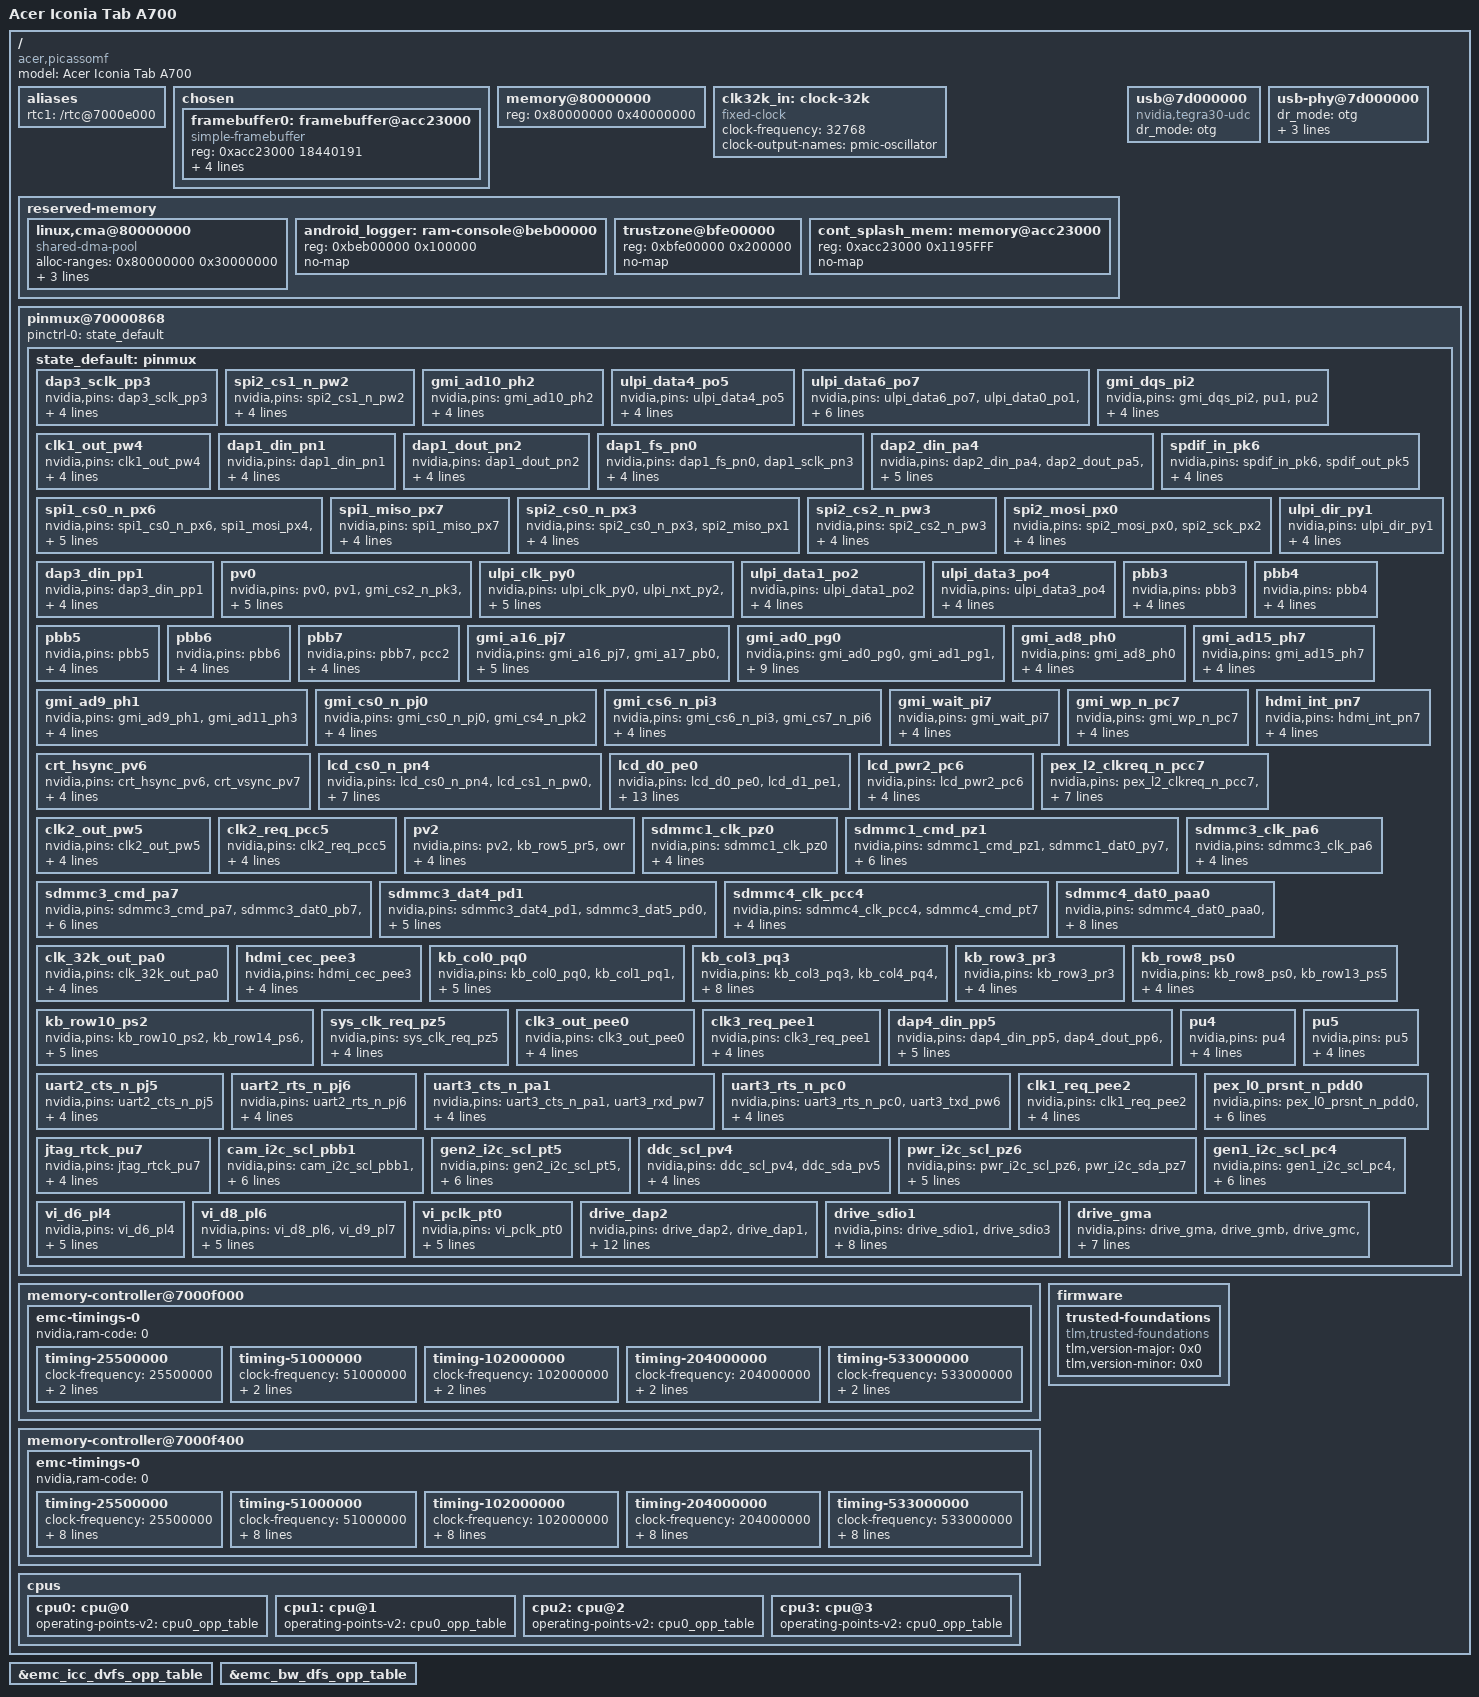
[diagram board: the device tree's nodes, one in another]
// SPDX-License-Identifier: GPL-2.0
/dts-v1/;
// /memreserve/ 0xbeb00000 0x100000;
#include <dt-bindings/input/gpio-keys.h>
#include <dt-bindings/input/input.h>
#include <dt-bindings/thermal/thermal.h>

#include "tegra30.dtsi"
#include "tegra30-cpu-opp.dtsi"
#include "tegra30-cpu-opp-microvolt.dtsi"

/ {
	model = "Acer Iconia Tab A700";
	compatible = "acer,picassomf", "nvidia,tegra30";

	aliases {
		rtc1 = "/rtc@7000e000";
	};

	chosen {
            #address-cells = <1>;
            #size-cells = <1>;
            ranges;

            framebuffer0: framebuffer@acc23000 {
                compatible = "simple-framebuffer";
                reg = <0xacc23000 18440191>;
                width = <1920>;
                height = <1200>;
                stride = <7680>;
                format = "a8r8g8b8";
                status = "okay";
            };
	};

	memory@80000000 {
		reg = <0x80000000 0x40000000>;
	};

	clk32k_in: clock-32k {
		compatible = "fixed-clock";
		#clock-cells = <0>;
		clock-frequency = <32768>;
		clock-output-names = "pmic-oscillator";
	};

	reserved-memory {
		#address-cells = <1>;
		#size-cells = <1>;
		ranges;

		linux,cma@80000000 {
			compatible = "shared-dma-pool";
			alloc-ranges = <0x80000000 0x30000000>;
			size = <0x10000000>; /* 256MiB */
			linux,cma-default;
			reusable;
		};

		android_logger: ram-console@beb00000 {
			reg = <0xbeb00000 0x100000>;
			no-map;
		};

		trustzone@bfe00000 {
			reg = <0xbfe00000 0x200000>;
			no-map;
		};

		cont_splash_mem: memory@acc23000 {
			reg = <0xacc23000 0x1195FFF>;
			no-map;
		};
	};

        usb@7d000000 {
                compatible = "nvidia,tegra30-udc";
                status = "okay";
                dr_mode = "otg";
        };

        usb-phy@7d000000 {
                status = "okay";
                dr_mode = "otg";
                nvidia,hssync-start-delay = <0>;
                nvidia,xcvr-lsfslew = <2>;
                nvidia,xcvr-lsrslew = <2>;
        };

    pinmux@70000868 {
        pinctrl-names = "default";
        pinctrl-0 = <&state_default>;

        state_default: pinmux {
            dap3_sclk_pp3 {
                nvidia,pins = "dap3_sclk_pp3";
                nvidia,function = "i2s2";
                nvidia,pull = <TEGRA_PIN_PULL_DOWN>;
                nvidia,tristate = <TEGRA_PIN_DISABLE>;
                nvidia,enable-input = <TEGRA_PIN_DISABLE>;
            };

            spi2_cs1_n_pw2 {
                nvidia,pins = "spi2_cs1_n_pw2";
                nvidia,function = "spi2";
                nvidia,pull = <TEGRA_PIN_PULL_UP>;
                nvidia,tristate = <TEGRA_PIN_ENABLE>;
                nvidia,enable-input = <TEGRA_PIN_ENABLE>;
            };

            gmi_ad10_ph2 {
                nvidia,pins = "gmi_ad10_ph2";
                nvidia,function = "nand";
                nvidia,pull = <TEGRA_PIN_PULL_DOWN>;
                nvidia,tristate = <TEGRA_PIN_DISABLE>;
                nvidia,enable-input = <TEGRA_PIN_DISABLE>;
            };

            ulpi_data4_po5 {
                nvidia,pins = "ulpi_data4_po5";
                nvidia,function = "uarta";
                nvidia,pull = <TEGRA_PIN_PULL_UP>;
                nvidia,tristate = <TEGRA_PIN_DISABLE>;
                nvidia,enable-input = <TEGRA_PIN_ENABLE>;
            };

            ulpi_data6_po7 {
                nvidia,pins = "ulpi_data6_po7", "ulpi_data0_po1", "ulpi_data2_po3", "ulpi_data5_po6", "ulpi_data7_po0";
                nvidia,function = "uarta";
                nvidia,pull = <TEGRA_PIN_PULL_NONE>;
                nvidia,tristate = <TEGRA_PIN_DISABLE>;
                nvidia,enable-input = <TEGRA_PIN_DISABLE>;
            };

            gmi_dqs_pi2 {
                nvidia,pins = "gmi_dqs_pi2", "pu1", "pu2";
                nvidia,function = "rsvd1";
                nvidia,pull = <TEGRA_PIN_PULL_NONE>;
                nvidia,tristate = <TEGRA_PIN_DISABLE>;
                nvidia,enable-input = <TEGRA_PIN_DISABLE>;
            };

            clk1_out_pw4 {
                nvidia,pins = "clk1_out_pw4";
                nvidia,function = "extperiph1";
                nvidia,pull = <TEGRA_PIN_PULL_NONE>;
                nvidia,tristate = <TEGRA_PIN_DISABLE>;
                nvidia,enable-input = <TEGRA_PIN_ENABLE>;
            };

            dap1_din_pn1 {
                nvidia,pins = "dap1_din_pn1";
                nvidia,function = "i2s0";
                nvidia,pull = <TEGRA_PIN_PULL_DOWN>;
                nvidia,tristate = <TEGRA_PIN_DISABLE>;
                nvidia,enable-input = <TEGRA_PIN_DISABLE>;
            };

            dap1_dout_pn2 {
                nvidia,pins = "dap1_dout_pn2";
                nvidia,function = "i2s0";
                nvidia,pull = <TEGRA_PIN_PULL_DOWN>;
                nvidia,tristate = <TEGRA_PIN_ENABLE>;
                nvidia,enable-input = <TEGRA_PIN_ENABLE>;
            };

            dap1_fs_pn0 {
                nvidia,pins = "dap1_fs_pn0", "dap1_sclk_pn3";
                nvidia,function = "i2s0";
                nvidia,pull = <TEGRA_PIN_PULL_NONE>;
                nvidia,tristate = <TEGRA_PIN_DISABLE>;
                nvidia,enable-input = <TEGRA_PIN_DISABLE>;
            };

            dap2_din_pa4 {
                nvidia,pins = "dap2_din_pa4", "dap2_dout_pa5", "dap2_fs_pa2", "dap2_sclk_pa3";
                nvidia,function = "i2s1";
                nvidia,pull = <TEGRA_PIN_PULL_NONE>;
                nvidia,tristate = <TEGRA_PIN_DISABLE>;
                nvidia,enable-input = <TEGRA_PIN_ENABLE>;
            };

            spdif_in_pk6 {
                nvidia,pins = "spdif_in_pk6", "spdif_out_pk5";
                nvidia,function = "spdif";
                nvidia,pull = <TEGRA_PIN_PULL_NONE>;
                nvidia,tristate = <TEGRA_PIN_DISABLE>;
                nvidia,enable-input = <TEGRA_PIN_DISABLE>;
            };

            spi1_cs0_n_px6 {
                nvidia,pins = "spi1_cs0_n_px6", "spi1_mosi_px4", "spi1_sck_px5";
                nvidia,function = "spi1";
                nvidia,pull = <TEGRA_PIN_PULL_NONE>;
                nvidia,tristate = <TEGRA_PIN_DISABLE>;
                nvidia,enable-input = <TEGRA_PIN_DISABLE>;
            };

            spi1_miso_px7 {
                nvidia,pins = "spi1_miso_px7";
                nvidia,function = "spi1";
                nvidia,pull = <TEGRA_PIN_PULL_DOWN>;
                nvidia,tristate = <TEGRA_PIN_ENABLE>;
                nvidia,enable-input = <TEGRA_PIN_ENABLE>;
            };

            spi2_cs0_n_px3 {
                nvidia,pins = "spi2_cs0_n_px3", "spi2_miso_px1";
                nvidia,function = "spi2";
                nvidia,pull = <TEGRA_PIN_PULL_NONE>;
                nvidia,tristate = <TEGRA_PIN_ENABLE>;
                nvidia,enable-input = <TEGRA_PIN_ENABLE>;
            };

            spi2_cs2_n_pw3 {
                nvidia,pins = "spi2_cs2_n_pw3";
                nvidia,function = "spi2";
                nvidia,pull = <TEGRA_PIN_PULL_DOWN>;
                nvidia,tristate = <TEGRA_PIN_ENABLE>;
                nvidia,enable-input = <TEGRA_PIN_ENABLE>;
            };

            spi2_mosi_px0 {
                nvidia,pins = "spi2_mosi_px0", "spi2_sck_px2";
                nvidia,function = "spi2";
                nvidia,pull = <TEGRA_PIN_PULL_NONE>;
                nvidia,tristate = <TEGRA_PIN_DISABLE>;
                nvidia,enable-input = <TEGRA_PIN_DISABLE>;
            };

            dap3_din_pp1 {
                nvidia,pins = "dap3_din_pp1";
                nvidia,function = "i2s2";
                nvidia,pull = <TEGRA_PIN_PULL_NONE>;
                nvidia,tristate = <TEGRA_PIN_DISABLE>;
                nvidia,enable-input = <TEGRA_PIN_DISABLE>;
            };

            pv0 {
                nvidia,pins = "pv0", "pv1", "gmi_cs2_n_pk3", "gmi_iordy_pi5";
                nvidia,function = "rsvd1";
                nvidia,pull = <TEGRA_PIN_PULL_NONE>;
                nvidia,tristate = <TEGRA_PIN_ENABLE>;
                nvidia,enable-input = <TEGRA_PIN_ENABLE>;
            };

            ulpi_clk_py0 {
                nvidia,pins = "ulpi_clk_py0", "ulpi_nxt_py2", "ulpi_stp_py3";
                nvidia,function = "uartd";
                nvidia,pull = <TEGRA_PIN_PULL_NONE>;
                nvidia,tristate = <TEGRA_PIN_DISABLE>;
                nvidia,enable-input = <TEGRA_PIN_DISABLE>;
            };

            ulpi_data1_po2 {
                nvidia,pins = "ulpi_data1_po2";
                nvidia,function = "uarta";
                nvidia,pull = <TEGRA_PIN_PULL_NONE>;
                nvidia,tristate = <TEGRA_PIN_DISABLE>;
                nvidia,enable-input = <TEGRA_PIN_ENABLE>;
            };

            ulpi_data3_po4 {
                nvidia,pins = "ulpi_data3_po4";
                nvidia,function = "uarta";
                nvidia,pull = <TEGRA_PIN_PULL_NONE>;
                nvidia,tristate = <TEGRA_PIN_ENABLE>;
                nvidia,enable-input = <TEGRA_PIN_ENABLE>;
            };

            ulpi_dir_py1 {
                nvidia,pins = "ulpi_dir_py1";
                nvidia,function = "uartd";
                nvidia,pull = <TEGRA_PIN_PULL_NONE>;
                nvidia,tristate = <TEGRA_PIN_DISABLE>;
                nvidia,enable-input = <TEGRA_PIN_ENABLE>;
            };

            pbb3 {
                nvidia,pins = "pbb3";
                nvidia,function = "vgp3";
                nvidia,pull = <TEGRA_PIN_PULL_NONE>;
                nvidia,tristate = <TEGRA_PIN_DISABLE>;
                nvidia,enable-input = <TEGRA_PIN_DISABLE>;
            };

            pbb4 {
                nvidia,pins = "pbb4";
                nvidia,function = "vgp4";
                nvidia,pull = <TEGRA_PIN_PULL_NONE>;
                nvidia,tristate = <TEGRA_PIN_DISABLE>;
                nvidia,enable-input = <TEGRA_PIN_DISABLE>;
            };

            pbb5 {
                nvidia,pins = "pbb5";
                nvidia,function = "vgp5";
                nvidia,pull = <TEGRA_PIN_PULL_NONE>;
                nvidia,tristate = <TEGRA_PIN_DISABLE>;
                nvidia,enable-input = <TEGRA_PIN_DISABLE>;
            };

            pbb6 {
                nvidia,pins = "pbb6";
                nvidia,function = "vgp6";
                nvidia,pull = <TEGRA_PIN_PULL_NONE>;
                nvidia,tristate = <TEGRA_PIN_ENABLE>;
                nvidia,enable-input = <TEGRA_PIN_ENABLE>;
            };

            pbb7 {
                nvidia,pins = "pbb7", "pcc2";
                nvidia,function = "i2s4";
                nvidia,pull = <TEGRA_PIN_PULL_NONE>;
                nvidia,tristate = <TEGRA_PIN_DISABLE>;
                nvidia,enable-input = <TEGRA_PIN_DISABLE>;
            };

            gmi_a16_pj7 {
                nvidia,pins = "gmi_a16_pj7", "gmi_a17_pb0", "gmi_a18_pb1";
                nvidia,function = "spi4";
                nvidia,pull = <TEGRA_PIN_PULL_NONE>;
                nvidia,tristate = <TEGRA_PIN_DISABLE>;
                nvidia,enable-input = <TEGRA_PIN_DISABLE>;
            };



            gmi_ad0_pg0 {
                nvidia,pins = "gmi_ad0_pg0", "gmi_ad1_pg1", "gmi_ad2_pg2", "gmi_ad3_pg3", "gmi_ad4_pg4", "gmi_ad5_pg5", "gmi_ad6_pg6", "gmi_ad7_pg7", "gmi_ad12_ph4", "gmi_ad13_ph5", "gmi_ad14_ph6", "gmi_adv_n_pk0", "gmi_clk_pk1", "gmi_cs1_n_pj2", "gmi_cs3_n_pk4", "gmi_oe_n_pi1", "gmi_wr_n_pi0";
                nvidia,function = "nand";
                nvidia,pull = <TEGRA_PIN_PULL_NONE>;
                nvidia,tristate = <TEGRA_PIN_ENABLE>;
                nvidia,enable-input = <TEGRA_PIN_ENABLE>;
            };

            gmi_ad8_ph0 {
                nvidia,pins = "gmi_ad8_ph0";
                nvidia,function = "pwm0";
                nvidia,pull = <TEGRA_PIN_PULL_NONE>;
                nvidia,tristate = <TEGRA_PIN_DISABLE>;
                nvidia,enable-input = <TEGRA_PIN_DISABLE>;
            };

            gmi_ad9_ph1 {
                nvidia,pins = "gmi_ad9_ph1", "gmi_ad11_ph3";
                nvidia,function = "nand";
                nvidia,pull = <TEGRA_PIN_PULL_NONE>;
                nvidia,tristate = <TEGRA_PIN_DISABLE>;
                nvidia,enable-input = <TEGRA_PIN_DISABLE>;
            };

            gmi_ad15_ph7 {
                nvidia,pins = "gmi_ad15_ph7";
                nvidia,function = "nand";
                nvidia,pull = <TEGRA_PIN_PULL_NONE>;
                nvidia,tristate = <TEGRA_PIN_DISABLE>;
                nvidia,enable-input = <TEGRA_PIN_ENABLE>;
            };

            gmi_cs0_n_pj0 {
                nvidia,pins = "gmi_cs0_n_pj0", "gmi_cs4_n_pk2";
                nvidia,function = "nand";
                nvidia,pull = <TEGRA_PIN_PULL_UP>;
                nvidia,tristate = <TEGRA_PIN_ENABLE>;
                nvidia,enable-input = <TEGRA_PIN_ENABLE>;
            };

            gmi_cs6_n_pi3 {
                nvidia,pins = "gmi_cs6_n_pi3", "gmi_cs7_n_pi6";
                nvidia,function = "nand_alt";
                nvidia,pull = <TEGRA_PIN_PULL_NONE>;
                nvidia,tristate = <TEGRA_PIN_ENABLE>;
                nvidia,enable-input = <TEGRA_PIN_ENABLE>;
            };

            gmi_wait_pi7 {
                nvidia,pins = "gmi_wait_pi7";
                nvidia,function = "nand";
                nvidia,pull = <TEGRA_PIN_PULL_UP>;
                nvidia,tristate = <TEGRA_PIN_DISABLE>;
                nvidia,enable-input = <TEGRA_PIN_DISABLE>;
            };

            gmi_wp_n_pc7 {
                nvidia,pins = "gmi_wp_n_pc7";
                nvidia,function = "rsvd1";
                nvidia,pull = <TEGRA_PIN_PULL_UP>;
                nvidia,tristate = <TEGRA_PIN_DISABLE>;
                nvidia,enable-input = <TEGRA_PIN_ENABLE>;
            };

            crt_hsync_pv6 {
                nvidia,pins = "crt_hsync_pv6", "crt_vsync_pv7";
                nvidia,function = "crt";
                nvidia,pull = <TEGRA_PIN_PULL_NONE>;
                nvidia,tristate = <TEGRA_PIN_DISABLE>;
                nvidia,enable-input = <TEGRA_PIN_DISABLE>;
            };

            hdmi_int_pn7 {
                nvidia,pins = "hdmi_int_pn7";
                nvidia,function = "hdmi";
                nvidia,pull = <TEGRA_PIN_PULL_NONE>;
                nvidia,tristate = <TEGRA_PIN_ENABLE>;
                nvidia,enable-input = <TEGRA_PIN_ENABLE>;
            };

            lcd_cs0_n_pn4 {
                nvidia,pins = "lcd_cs0_n_pn4", "lcd_cs1_n_pw0", "lcd_dc0_pn6", "lcd_dc1_pd2", "lcd_m1_pw1", "lcd_pwr0_pb2", "lcd_pwr1_pc1", "lcd_sck_pz4", "lcd_sdin_pz2", "lcd_sdout_pn5", "lcd_wr_n_pz3";
                nvidia,function = "displaya";
                nvidia,pull = <TEGRA_PIN_PULL_NONE>;
                nvidia,tristate = <TEGRA_PIN_DISABLE>;
                nvidia,enable-input = <TEGRA_PIN_DISABLE>;
            };

            lcd_d0_pe0 {
                nvidia,pins = "lcd_d0_pe0", "lcd_d1_pe1", "lcd_d2_pe2", "lcd_d3_pe3", "lcd_d4_pe4", "lcd_d5_pe5", "lcd_d6_pe6", "lcd_d7_pe7", "lcd_d8_pf0", "lcd_d9_pf1", "lcd_d10_pf2", "lcd_d11_pf3", "lcd_d12_pf4", "lcd_d13_pf5", "lcd_d14_pf6", "lcd_d15_pf7", "lcd_d16_pm0", "lcd_d17_pm1", "lcd_d18_pm2", "lcd_d19_pm3", "lcd_d20_pm4", "lcd_d21_pm5", "lcd_d22_pm6", "lcd_d23_pm7", "lcd_de_pj1", "lcd_hsync_pj3", "lcd_pclk_pb3", "lcd_vsync_pj4";
                nvidia,function = "displaya";
                nvidia,pull = <TEGRA_PIN_PULL_NONE>;
                nvidia,tristate = <TEGRA_PIN_DISABLE>;
                nvidia,enable-input = <TEGRA_PIN_ENABLE>;
            };

            lcd_pwr2_pc6 {
                nvidia,pins = "lcd_pwr2_pc6";
                nvidia,function = "displaya";
                nvidia,pull = <TEGRA_PIN_PULL_DOWN>;
                nvidia,tristate = <TEGRA_PIN_DISABLE>;
                nvidia,enable-input = <TEGRA_PIN_DISABLE>;
            };

            pex_l2_clkreq_n_pcc7 {
                nvidia,pins = "pex_l2_clkreq_n_pcc7", "pex_l2_prsnt_n_pdd7", "pex_l2_rst_n_pcc6", "pex_wake_n_pdd3", "pex_l0_rst_n_pdd1", "pex_l1_rst_n_pdd5";
                nvidia,function = "pcie";
                nvidia,pull = <TEGRA_PIN_PULL_NONE>;
                nvidia,tristate = <TEGRA_PIN_DISABLE>;
                nvidia,enable-input = <TEGRA_PIN_DISABLE>;
            };

            clk2_out_pw5 {
                nvidia,pins = "clk2_out_pw5";
                nvidia,function = "extperiph2";
                nvidia,pull = <TEGRA_PIN_PULL_UP>;
                nvidia,tristate = <TEGRA_PIN_DISABLE>;
                nvidia,enable-input = <TEGRA_PIN_DISABLE>;
            };

            clk2_req_pcc5 {
                nvidia,pins = "clk2_req_pcc5";
                nvidia,function = "dap";
                nvidia,pull = <TEGRA_PIN_PULL_NONE>;
                nvidia,tristate = <TEGRA_PIN_DISABLE>;
                nvidia,enable-input = <TEGRA_PIN_DISABLE>;
            };

            pv2 {
                nvidia,pins = "pv2", "kb_row5_pr5", "owr";
                nvidia,function = "owr";
                nvidia,pull = <TEGRA_PIN_PULL_NONE>;
                nvidia,tristate = <TEGRA_PIN_DISABLE>;
                nvidia,enable-input = <TEGRA_PIN_DISABLE>;
            };

            sdmmc1_clk_pz0 {
                nvidia,pins = "sdmmc1_clk_pz0";
                nvidia,function = "sdmmc1";
                nvidia,pull = <TEGRA_PIN_PULL_NONE>;
                nvidia,tristate = <TEGRA_PIN_DISABLE>;
                nvidia,enable-input = <TEGRA_PIN_ENABLE>;
            };

            sdmmc1_cmd_pz1 {
                nvidia,pins = "sdmmc1_cmd_pz1", "sdmmc1_dat0_py7", "sdmmc1_dat1_py6", "sdmmc1_dat2_py5", "sdmmc1_dat3_py4";
                nvidia,function = "sdmmc1";
                nvidia,pull = <TEGRA_PIN_PULL_UP>;
                nvidia,tristate = <TEGRA_PIN_DISABLE>;
                nvidia,enable-input = <TEGRA_PIN_ENABLE>;
            };

            sdmmc3_clk_pa6 {
                nvidia,pins = "sdmmc3_clk_pa6";
                nvidia,function = "sdmmc3";
                nvidia,pull = <TEGRA_PIN_PULL_NONE>;
                nvidia,tristate = <TEGRA_PIN_DISABLE>;
                nvidia,enable-input = <TEGRA_PIN_ENABLE>;
            };

            sdmmc3_cmd_pa7 {
                nvidia,pins = "sdmmc3_cmd_pa7", "sdmmc3_dat0_pb7", "sdmmc3_dat1_pb6", "sdmmc3_dat2_pb5", "sdmmc3_dat3_pb4";
                nvidia,function = "sdmmc3";
                nvidia,pull = <TEGRA_PIN_PULL_UP>;
                nvidia,tristate = <TEGRA_PIN_DISABLE>;
                nvidia,enable-input = <TEGRA_PIN_ENABLE>;
            };

            sdmmc3_dat4_pd1 {
                nvidia,pins = "sdmmc3_dat4_pd1", "sdmmc3_dat5_pd0", "sdmmc3_dat6_pd3", "sdmmc3_dat7_pd4";
                nvidia,function = "sdmmc3";
                nvidia,pull = <TEGRA_PIN_PULL_NONE>;
                nvidia,tristate = <TEGRA_PIN_DISABLE>;
                nvidia,enable-input = <TEGRA_PIN_DISABLE>;
            };

            sdmmc4_clk_pcc4 {
                nvidia,pins = "sdmmc4_clk_pcc4", "sdmmc4_cmd_pt7";
                nvidia,function = "sdmmc4";
                nvidia,pull = <TEGRA_PIN_PULL_NONE>;
                nvidia,tristate = <TEGRA_PIN_DISABLE>;
                nvidia,enable-input = <TEGRA_PIN_ENABLE>;
            };

            sdmmc4_dat0_paa0 {
                nvidia,pins = "sdmmc4_dat0_paa0", "sdmmc4_dat1_paa1", "sdmmc4_dat2_paa2", "sdmmc4_dat3_paa3", "sdmmc4_dat4_paa4", "sdmmc4_dat5_paa5", "sdmmc4_dat6_paa6", "sdmmc4_dat7_paa7";
                nvidia,function = "sdmmc4";
                nvidia,pull = <TEGRA_PIN_PULL_UP>;
                nvidia,tristate = <TEGRA_PIN_DISABLE>;
                nvidia,enable-input = <TEGRA_PIN_ENABLE>;
            };

            clk_32k_out_pa0 {
                nvidia,pins = "clk_32k_out_pa0";
                nvidia,function = "blink";
                nvidia,pull = <TEGRA_PIN_PULL_NONE>;
                nvidia,tristate = <TEGRA_PIN_DISABLE>;
                nvidia,enable-input = <TEGRA_PIN_DISABLE>;
            };

            hdmi_cec_pee3 {
                nvidia,pins = "hdmi_cec_pee3";
                nvidia,function = "cec";
                nvidia,pull = <TEGRA_PIN_PULL_NONE>;
                nvidia,tristate = <TEGRA_PIN_DISABLE>;
                nvidia,enable-input = <TEGRA_PIN_ENABLE>;
            };

            kb_col0_pq0 {
                nvidia,pins = "kb_col0_pq0", "kb_col1_pq1", "kb_col2_pq2", "kb_row12_ps4";
                nvidia,function = "kbc";
                nvidia,pull = <TEGRA_PIN_PULL_UP>;
                nvidia,tristate = <TEGRA_PIN_ENABLE>;
                nvidia,enable-input = <TEGRA_PIN_ENABLE>;
            };

            kb_col3_pq3 {
                nvidia,pins = "kb_col3_pq3", "kb_col4_pq4", "kb_col5_pq5", "kb_col6_pq6", "kb_col7_pq7", "kb_row0_pr0", "kb_row2_pr2", "kb_row4_pr4", "kb_row6_pr6", "kb_row7_pr7", "kb_row9_ps1", "kb_row11_ps3";
                nvidia,function = "kbc";
                nvidia,pull = <TEGRA_PIN_PULL_NONE>;
                nvidia,tristate = <TEGRA_PIN_DISABLE>;
                nvidia,enable-input = <TEGRA_PIN_DISABLE>;
            };

            kb_row3_pr3 {
                nvidia,pins = "kb_row3_pr3";
                nvidia,function = "kbc";
                nvidia,pull = <TEGRA_PIN_PULL_UP>;
                nvidia,tristate = <TEGRA_PIN_DISABLE>;
                nvidia,enable-input = <TEGRA_PIN_DISABLE>;
            };

            kb_row8_ps0 {
                nvidia,pins = "kb_row8_ps0", "kb_row13_ps5";
                nvidia,function = "kbc";
                nvidia,pull = <TEGRA_PIN_PULL_DOWN>;
                nvidia,tristate = <TEGRA_PIN_ENABLE>;
                nvidia,enable-input = <TEGRA_PIN_ENABLE>;
            };

            kb_row10_ps2 {
                nvidia,pins = "kb_row10_ps2", "kb_row14_ps6", "kb_row15_ps7";
                nvidia,function = "kbc";
                nvidia,pull = <TEGRA_PIN_PULL_NONE>;
                nvidia,tristate = <TEGRA_PIN_ENABLE>;
                nvidia,enable-input = <TEGRA_PIN_ENABLE>;
            };

            sys_clk_req_pz5 {
                nvidia,pins = "sys_clk_req_pz5";
                nvidia,function = "sysclk";
                nvidia,pull = <TEGRA_PIN_PULL_NONE>;
                nvidia,tristate = <TEGRA_PIN_DISABLE>;
                nvidia,enable-input = <TEGRA_PIN_DISABLE>;
            };

            clk3_out_pee0 {
                nvidia,pins = "clk3_out_pee0";
                nvidia,function = "extperiph3";
                nvidia,pull = <TEGRA_PIN_PULL_NONE>;
                nvidia,tristate = <TEGRA_PIN_DISABLE>;
                nvidia,enable-input = <TEGRA_PIN_DISABLE>;
            };

            clk3_req_pee1 {
                nvidia,pins = "clk3_req_pee1";
                nvidia,function = "dev3";
                nvidia,pull = <TEGRA_PIN_PULL_NONE>;
                nvidia,tristate = <TEGRA_PIN_DISABLE>;
                nvidia,enable-input = <TEGRA_PIN_DISABLE>;
            };

            dap4_din_pp5 {
                nvidia,pins = "dap4_din_pp5", "dap4_dout_pp6", "dap4_fs_pp4", "dap4_sclk_pp7";
                nvidia,function = "i2s3";
                nvidia,pull = <TEGRA_PIN_PULL_NONE>;
                nvidia,tristate = <TEGRA_PIN_DISABLE>;
                nvidia,enable-input = <TEGRA_PIN_ENABLE>;
            };

            pu4 {
                nvidia,pins = "pu4";
                nvidia,function = "pwm1";
                nvidia,pull = <TEGRA_PIN_PULL_NONE>;
                nvidia,tristate = <TEGRA_PIN_DISABLE>;
                nvidia,enable-input = <TEGRA_PIN_DISABLE>;
            };

            pu5 {
                nvidia,pins = "pu5";
                nvidia,function = "pwm2";
                nvidia,pull = <TEGRA_PIN_PULL_NONE>;
                nvidia,tristate = <TEGRA_PIN_ENABLE>;
                nvidia,enable-input = <TEGRA_PIN_ENABLE>;
            };

            uart2_cts_n_pj5 {
                nvidia,pins = "uart2_cts_n_pj5";
                nvidia,function = "uartb";
                nvidia,pull = <TEGRA_PIN_PULL_NONE>;
                nvidia,tristate = <TEGRA_PIN_DISABLE>;
                nvidia,enable-input = <TEGRA_PIN_ENABLE>;
            };

            uart2_rts_n_pj6 {
                nvidia,pins = "uart2_rts_n_pj6";
                nvidia,function = "uartb";
                nvidia,pull = <TEGRA_PIN_PULL_NONE>;
                nvidia,tristate = <TEGRA_PIN_DISABLE>;
                nvidia,enable-input = <TEGRA_PIN_DISABLE>;
            };

            uart3_cts_n_pa1 {
                nvidia,pins = "uart3_cts_n_pa1", "uart3_rxd_pw7";
                nvidia,function = "uartc";
                nvidia,pull = <TEGRA_PIN_PULL_NONE>;
                nvidia,tristate = <TEGRA_PIN_DISABLE>;
                nvidia,enable-input = <TEGRA_PIN_ENABLE>;
            };

            uart3_rts_n_pc0 {
                nvidia,pins = "uart3_rts_n_pc0", "uart3_txd_pw6";
                nvidia,function = "uartc";
                nvidia,pull = <TEGRA_PIN_PULL_NONE>;
                nvidia,tristate = <TEGRA_PIN_DISABLE>;
                nvidia,enable-input = <TEGRA_PIN_DISABLE>;
            };

            clk1_req_pee2 {
                nvidia,pins = "clk1_req_pee2";
                nvidia,function = "dap";
                nvidia,pull = <TEGRA_PIN_PULL_NONE>;
                nvidia,tristate = <TEGRA_PIN_DISABLE>;
                nvidia,enable-input = <TEGRA_PIN_ENABLE>;
            };

            pex_l0_prsnt_n_pdd0 {
                nvidia,pins = "pex_l0_prsnt_n_pdd0", "pex_l0_clkreq_n_pdd2", "pex_l1_prsnt_n_pdd4", "pex_l1_clkreq_n_pdd6";
                nvidia,function = "pcie";
                nvidia,pull = <TEGRA_PIN_PULL_NONE>;
                nvidia,tristate = <TEGRA_PIN_DISABLE>;
                nvidia,enable-input = <TEGRA_PIN_ENABLE>;
            };

            jtag_rtck_pu7 {
                nvidia,pins = "jtag_rtck_pu7";
                nvidia,function = "rtck";
                nvidia,pull = <TEGRA_PIN_PULL_NONE>;
                nvidia,tristate = <TEGRA_PIN_DISABLE>;
                nvidia,enable-input = <TEGRA_PIN_DISABLE>;
            };


            cam_i2c_scl_pbb1 {
                nvidia,pins = "cam_i2c_scl_pbb1", "cam_i2c_sda_pbb2";
                nvidia,function = "i2c3";
                nvidia,pull = <TEGRA_PIN_PULL_NONE>;
                nvidia,tristate = <TEGRA_PIN_DISABLE>;
                nvidia,enable-input = <TEGRA_PIN_ENABLE>;
                nvidia,open-drain = <TEGRA_PIN_ENABLE>;

            };


            gen2_i2c_scl_pt5 {
                nvidia,pins = "gen2_i2c_scl_pt5", "gen2_i2c_sda_pt6";
                nvidia,function = "i2c2";
                nvidia,pull = <TEGRA_PIN_PULL_NONE>;
                nvidia,tristate = <TEGRA_PIN_DISABLE>;
                nvidia,enable-input = <TEGRA_PIN_ENABLE>;
                nvidia,open-drain = <TEGRA_PIN_ENABLE>;

            };


            ddc_scl_pv4 {
                nvidia,pins = "ddc_scl_pv4", "ddc_sda_pv5";
                nvidia,function = "i2c4";
                nvidia,pull = <TEGRA_PIN_PULL_NONE>;
                nvidia,tristate = <TEGRA_PIN_DISABLE>;
                nvidia,enable-input = <TEGRA_PIN_ENABLE>;
                // nvidia,open-drain = <TEGRA_PIN_ENABLE>;

            };


            pwr_i2c_scl_pz6 {
                nvidia,pins = "pwr_i2c_scl_pz6", "pwr_i2c_sda_pz7";
                nvidia,function = "i2cpwr";
                nvidia,pull = <TEGRA_PIN_PULL_NONE>;
                nvidia,tristate = <TEGRA_PIN_DISABLE>;
                nvidia,enable-input = <TEGRA_PIN_ENABLE>;
                nvidia,open-drain = <TEGRA_PIN_ENABLE>;

            };


            gen1_i2c_scl_pc4 {
                nvidia,pins = "gen1_i2c_scl_pc4", "gen1_i2c_sda_pc5";
                nvidia,function = "i2c1";
                nvidia,pull = <TEGRA_PIN_PULL_NONE>;
                nvidia,tristate = <TEGRA_PIN_DISABLE>;
                nvidia,enable-input = <TEGRA_PIN_ENABLE>;
                nvidia,open-drain = <TEGRA_PIN_ENABLE>;

            };


            vi_d6_pl4 {
                nvidia,pins = "vi_d6_pl4";
                nvidia,function = "vi";
                nvidia,pull = <TEGRA_PIN_PULL_NONE>;
                nvidia,tristate = <TEGRA_PIN_DISABLE>;
                nvidia,enable-input = <TEGRA_PIN_DISABLE>;
                nvidia,ioreset = <0>;
            };

            vi_d8_pl6 {
                nvidia,pins = "vi_d8_pl6", "vi_d9_pl7";
                nvidia,function = "sdmmc2";
                nvidia,pull = <TEGRA_PIN_PULL_NONE>;
                nvidia,tristate = <TEGRA_PIN_DISABLE>;
                nvidia,enable-input = <TEGRA_PIN_ENABLE>;
                nvidia,ioreset = <0>;
            };

            vi_pclk_pt0 {
                nvidia,pins = "vi_pclk_pt0";
                nvidia,function = "rsvd1";
                nvidia,pull = <TEGRA_PIN_PULL_UP>;
                nvidia,tristate = <TEGRA_PIN_ENABLE>;
                nvidia,enable-input = <TEGRA_PIN_ENABLE>;
                nvidia,ioreset = <0>;
            };

            drive_dap2 {
                nvidia,pins = "drive_dap2", "drive_dap1", "drive_dbg", "drive_at5", "drive_gme", "drive_ddc", "drive_ao1", "drive_uart3";
                nvidia,high-speed-mode = <0>;
                nvidia,schmitt = <TEGRA_PIN_ENABLE>;
                nvidia,low-power-mode = <TEGRA_PIN_LP_DRIVE_DIV_1>;
                nvidia,pull-down-strength = <31>;
                nvidia,pull-up-strength = <31>;
                nvidia,slew-rate-rising = <TEGRA_PIN_SLEW_RATE_FASTEST>;
                nvidia,slew-rate-falling = <TEGRA_PIN_SLEW_RATE_FASTEST>;
            };

            drive_sdio1 {
                nvidia,pins = "drive_sdio1", "drive_sdio3";
                nvidia,high-speed-mode = <0>;
                nvidia,schmitt = <TEGRA_PIN_DISABLE>;
                // nvidia,low-power-mode = <TEGRA_PIN_LP_DRIVE_DIV_1>;
                nvidia,pull-down-strength = <46>;
                nvidia,pull-up-strength = <42>;
                nvidia,slew-rate-rising = <TEGRA_PIN_SLEW_RATE_FAST>;
                nvidia,slew-rate-falling = <TEGRA_PIN_SLEW_RATE_FAST>;
            };

            drive_gma {
                nvidia,pins = "drive_gma", "drive_gmb", "drive_gmc", "drive_gmd";
                nvidia,pull-down-strength = <9>;
                nvidia,pull-up-strength = <9>;
                nvidia,slew-rate-rising = <TEGRA_PIN_SLEW_RATE_SLOWEST>;
                nvidia,slew-rate-falling = <TEGRA_PIN_SLEW_RATE_SLOWEST>;
            };

        };
    };

memory-controller@7000f000 {
		emc-timings-0 {
			/* elpida */
			nvidia,ram-code = <0>;

			timing-25500000 {
				clock-frequency = <25500000>;

				nvidia,emem-configuration = < 0x00030003 0xc0000020
					0x00000001 0x00000001 0x00000002 0x00000000
					0x00000003 0x00000001 0x00000002 0x00000004
					0x00000001 0x00000000 0x00000002 0x00000002
					0x02020001 0x00060402 0x73e30303 0x001f0000 >;
			};

			timing-51000000 {
				clock-frequency = <51000000>;

				nvidia,emem-configuration = < 0x00010003 0xc0000020
					0x00000001 0x00000001 0x00000002 0x00000000
					0x00000003 0x00000001 0x00000002 0x00000004
					0x00000001 0x00000000 0x00000002 0x00000002
					0x02020001 0x00060402 0x72c30303 0x001f0000 >;
			};

			timing-102000000 {
				clock-frequency = <102000000>;

				nvidia,emem-configuration = < 0x00000003 0xc0000030
					0x00000001 0x00000001 0x00000003 0x00000001
					0x00000003 0x00000001 0x00000002 0x00000004
					0x00000001 0x00000000 0x00000002 0x00000002
					0x02020001 0x00060403 0x72430504 0x001f0000 >;
			};

			timing-204000000 {
				clock-frequency = <204000000>;

				nvidia,emem-configuration = < 0x00000006 0xc0000025
					0x00000001 0x00000001 0x00000006 0x00000003
					0x00000005 0x00000001 0x00000002 0x00000004
					0x00000001 0x00000000 0x00000003 0x00000002
					0x02030001 0x00070506 0x71e40a07 0x001f0000 >;
			};

			timing-533000000 {
				clock-frequency = <533000000>;

				nvidia,emem-configuration = < 0x0000000f 0xc0000060
					0x00000003 0x00000004 0x00000010 0x0000000a
					0x0000000d 0x00000002 0x00000002 0x00000008
					0x00000002 0x00000000 0x00000004 0x00000005
					0x05040002 0x00110b10 0x71c81811 0x001f0000 >;
			};
		};
	};

	memory-controller@7000f400 {
		emc-timings-0 {
			/* elpida */
			nvidia,ram-code = <0>;

			timing-25500000 {
				clock-frequency = <25500000>;

				nvidia,emc-auto-cal-interval = <0x001fffff>;
				nvidia,emc-mode-1 = <0x00010022>;
				nvidia,emc-mode-2 = <0x00020001>;
				nvidia,emc-mode-reset = <0x00000000>;
				nvidia,emc-zcal-cnt-long = <0x00000009>;
				nvidia,emc-cfg-periodic-qrst;

				nvidia,emc-configuration =  < 0x00000001
					0x00000003 0x00000002 0x00000002 0x00000004
					0x00000004 0x00000001 0x00000005 0x00000002
					0x00000002 0x00000001 0x00000001 0x00000000
					0x00000001 0x00000003 0x00000001 0x0000000b
					0x00000009 0x00000060 0x00000000 0x00000018
					0x00000001 0x00000001 0x00000002 0x00000000
					0x00000001 0x00000007 0x00000004 0x00000004
					0x00000003 0x00000008 0x00000004 0x00000004
					0x00000002 0x0000006b 0x00000004 0x00000004
					0x00000000 0x00000000 0x00004282 0x00780084
					0x00008000 0x000fc000 0x000fc000 0x000fc000
					0x000fc000 0x000fc000 0x000fc000 0x000fc000
					0x000fc000 0x00000000 0x00000000 0x00000000
					0x00000000 0x00000000 0x00000000 0x00000000
					0x00000000 0x00000000 0x00000000 0x00000000
					0x00000000 0x00000000 0x00000000 0x00000000
					0x00000000 0x000fc000 0x000fc000 0x000fc000
					0x000fc000 0x00100220 0x0800201c 0x00000000
					0x77ffc004 0x01f1f008 0x00000000 0x00000007
					0x08000068 0x08000000 0x00000802 0x00064000
					0x0000000a 0x00090009 0xa0f10000 0x00000000
					0x00000000 0x800001c5 0xe0000000 0xff00ff00 >;
			};

			timing-51000000 {
				clock-frequency = <51000000>;

				nvidia,emc-auto-cal-interval = <0x001fffff>;
				nvidia,emc-mode-1 = <0x00010022>;
				nvidia,emc-mode-2 = <0x00020001>;
				nvidia,emc-mode-reset = <0x00000000>;
				nvidia,emc-zcal-cnt-long = <0x00000009>;
				nvidia,emc-cfg-periodic-qrst;

				nvidia,emc-configuration =  < 0x00000003
					0x00000006 0x00000002 0x00000002 0x00000004
					0x00000004 0x00000001 0x00000005 0x00000002
					0x00000002 0x00000001 0x00000001 0x00000000
					0x00000001 0x00000003 0x00000001 0x0000000b
					0x00000009 0x000000c0 0x00000000 0x00000030
					0x00000001 0x00000001 0x00000002 0x00000000
					0x00000001 0x00000007 0x00000008 0x00000008
					0x00000003 0x00000008 0x00000004 0x00000004
					0x00000002 0x000000d5 0x00000004 0x00000004
					0x00000000 0x00000000 0x00004282 0x00780084
					0x00008000 0x000fc000 0x000fc000 0x000fc000
					0x000fc000 0x000fc000 0x000fc000 0x000fc000
					0x000fc000 0x00000000 0x00000000 0x00000000
					0x00000000 0x00000000 0x00000000 0x00000000
					0x00000000 0x00000000 0x00000000 0x00000000
					0x00000000 0x00000000 0x00000000 0x00000000
					0x00000000 0x000fc000 0x000fc000 0x000fc000
					0x000fc000 0x00100220 0x0800201c 0x00000000
					0x77ffc004 0x01f1f008 0x00000000 0x00000007
					0x08000068 0x08000000 0x00000802 0x00064000
					0x00000013 0x00090009 0xa0f10000 0x00000000
					0x00000000 0x80000287 0xe0000000 0xff00ff00 >;
			};

			timing-102000000 {
				clock-frequency = <102000000>;

				nvidia,emc-auto-cal-interval = <0x001fffff>;
				nvidia,emc-mode-1 = <0x00010022>;
				nvidia,emc-mode-2 = <0x00020001>;
				nvidia,emc-mode-reset = <0x00000000>;
				nvidia,emc-zcal-cnt-long = <0x0000000a>;
				nvidia,emc-cfg-periodic-qrst;

				nvidia,emc-configuration =  < 0x00000006
					0x0000000d 0x00000004 0x00000002 0x00000004
					0x00000004 0x00000001 0x00000005 0x00000002
					0x00000002 0x00000001 0x00000001 0x00000000
					0x00000001 0x00000003 0x00000001 0x0000000b
					0x00000009 0x00000181 0x00000000 0x00000060
					0x00000001 0x00000001 0x00000002 0x00000000
					0x00000001 0x00000007 0x0000000f 0x0000000f
					0x00000003 0x00000008 0x00000004 0x00000004
					0x00000002 0x000001a9 0x00000004 0x00000004
					0x00000000 0x00000000 0x00004282 0x00780084
					0x00008000 0x000fc000 0x000fc000 0x000fc000
					0x000fc000 0x000fc000 0x000fc000 0x000fc000
					0x000fc000 0x00000000 0x00000000 0x00000000
					0x00000000 0x00000000 0x00000000 0x00000000
					0x00000000 0x00000000 0x00000000 0x00000000
					0x00000000 0x00000000 0x00000000 0x00000000
					0x00000000 0x000fc000 0x000fc000 0x000fc000
					0x000fc000 0x00100220 0x0800201c 0x00000000
					0x77ffc004 0x01f1f008 0x00000000 0x00000007
					0x08000068 0x08000000 0x00000802 0x00064000
					0x00000025 0x00090009 0xa0f10000 0x00000000
					0x00000000 0x8000040b 0xe0000000 0xff00ff00 >;
			};

			timing-204000000 {
				clock-frequency = <204000000>;

				nvidia,emc-auto-cal-interval = <0x001fffff>;
				nvidia,emc-mode-1 = <0x00010042>;
				nvidia,emc-mode-2 = <0x00020001>;
				nvidia,emc-mode-reset = <0x00000000>;
				nvidia,emc-zcal-cnt-long = <0x00000013>;
				nvidia,emc-cfg-periodic-qrst;

				nvidia,emc-configuration =  < 0x0000000c
					0x0000001a 0x00000008 0x00000003 0x00000005
					0x00000004 0x00000001 0x00000006 0x00000003
					0x00000003 0x00000002 0x00000002 0x00000000
					0x00000001 0x00000003 0x00000001 0x0000000c
					0x0000000a 0x00000303 0x00000000 0x000000c0
					0x00000001 0x00000001 0x00000003 0x00000000
					0x00000001 0x00000007 0x0000001d 0x0000001d
					0x00000004 0x0000000b 0x00000005 0x00000004
					0x00000002 0x00000351 0x00000004 0x00000006
					0x00000000 0x00000000 0x00004282 0x00440084
					0x00008000 0x00080000 0x00080000 0x00080000
					0x00080000 0x00080000 0x00080000 0x00080000
					0x00080000 0x00000000 0x00000000 0x00000000
					0x00000000 0x00000000 0x00000000 0x00000000
					0x00000000 0x00000000 0x00000000 0x00000000
					0x00000000 0x00000000 0x00000000 0x00000000
					0x00000000 0x000b0000 0x000b0000 0x000b0000
					0x000b0000 0x000e0220 0x0800201c 0x00000000
					0x77ffc004 0x01f1f008 0x00000000 0x00000007
					0x08000068 0x08000000 0x00000802 0x00064000
					0x0000004a 0x00090009 0xa0f10000 0x00000000
					0x00000000 0x80000713 0xe0000000 0xff00ff00 >;
			};

			timing-533000000 {
				clock-frequency = <533000000>;

				nvidia,emc-auto-cal-interval = <0x001fffff>;
				nvidia,emc-mode-1 = <0x000100c2>;
				nvidia,emc-mode-2 = <0x00020006>;
				nvidia,emc-mode-reset = <0x00000000>;
				nvidia,emc-zcal-cnt-long = <0x00000030>;
				nvidia,emc-cfg-periodic-qrst;

				nvidia,emc-configuration =  < 0x0000001f
					0x00000045 0x00000016 0x00000009 0x00000008
					0x00000009 0x00000003 0x0000000d 0x00000009
					0x00000009 0x00000005 0x00000003 0x00000000
					0x00000004 0x0000000a 0x00000006 0x0000000d
					0x00000010 0x000007df 0x00000000 0x000001f7
					0x00000003 0x00000003 0x00000009 0x00000000
					0x00000001 0x0000000f 0x0000004b 0x0000004b
					0x00000008 0x0000001b 0x0000000c 0x00000004
					0x00000002 0x000008aa 0x00000000 0x00000004
					0x00000000 0x00000000 0x00006282 0xf0120091
					0x00008000 0x00000008 0x00000008 0x00000008
					0x00000008 0x00000008 0x00000008 0x00000008
					0x00000008 0x00000000 0x00000000 0x00000000
					0x00000000 0x00000000 0x00000000 0x00000000
					0x00000000 0x00000000 0x00000000 0x00000000
					0x00000000 0x00000000 0x00000000 0x00000000
					0x00000000 0x0000000c 0x0000000c 0x0000000c
					0x0000000c 0x00080220 0x0400003d 0x00000000
					0x77ffc004 0x01f1f408 0x00000000 0x00000007
					0x08000068 0x08000000 0x00000802 0x00064000
					0x000000c0 0x000e000e 0xa0f10505 0x00000000
					0x00000000 0x800010d9 0xe0000000 0xff00ff88 >;
			};
		};
	};


	cpus {
		cpu0: cpu@0 {
			operating-points-v2 = <&cpu0_opp_table>;
			// cpu-supply = <&vdd_cpu>;
			#cooling-cells = <2>;
		};

		cpu1: cpu@1 {
			operating-points-v2 = <&cpu0_opp_table>;
			// cpu-supply = <&vdd_cpu>;
			#cooling-cells = <2>;
		};

		cpu2: cpu@2 {
			operating-points-v2 = <&cpu0_opp_table>;
			// cpu-supply = <&vdd_cpu>;
			#cooling-cells = <2>;
		};

		cpu3: cpu@3 {
			operating-points-v2 = <&cpu0_opp_table>;
			// cpu-supply = <&vdd_cpu>;
			#cooling-cells = <2>;
		};
	};


	firmware {
		trusted-foundations {
			compatible = "tlm,trusted-foundations";
			tlm,version-major = <0x0>;
			tlm,version-minor = <0x0>;
		};
	};

};

&emc_icc_dvfs_opp_table {
	/delete-node/ opp-900000000-1350;
	/delete-node/ opp-625000000-1200;
	/delete-node/ opp-625000000-1250;
	/delete-node/ opp-667000000-1200;
	/delete-node/ opp-750000000-1300;
	/delete-node/ opp-800000000-1300;
};

&emc_bw_dfs_opp_table {
	/delete-node/ opp-900000000;
	/delete-node/ opp-625000000;
	/delete-node/ opp-667000000;
	/delete-node/ opp-750000000;
	/delete-node/ opp-800000000;
	/delete-node/ opp-533000000;
};
